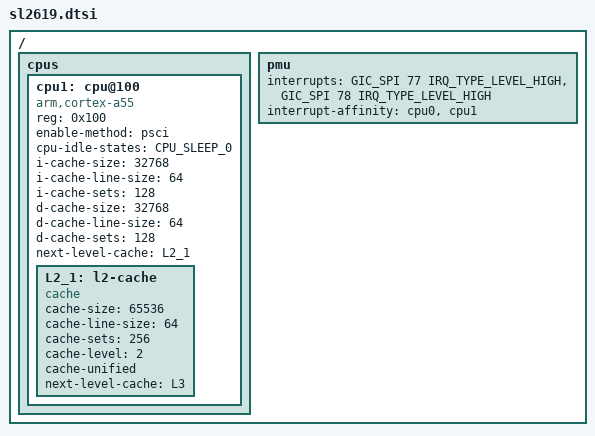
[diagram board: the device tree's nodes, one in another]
// SPDX-License-Identifier: (GPL-2.0 OR MIT)
/*
 * Copyright (C) 2025 Synaptics Incorporated
 *
 * Author: Jisheng Zhang <jszhang@kernel.org>
 */

#include "sl2613.dtsi"

/ {
	cpus {
		cpu1: cpu@100 {
			compatible = "arm,cortex-a55";
			device_type = "cpu";
			reg = <0x100>;
			enable-method = "psci";
			cpu-idle-states = <&CPU_SLEEP_0>;
			i-cache-size = <32768>;
			i-cache-line-size = <64>;
			i-cache-sets = <128>;
			d-cache-size = <32768>;
			d-cache-line-size = <64>;
			d-cache-sets = <128>;
			next-level-cache = <&L2_1>;

			L2_1: l2-cache {
				compatible = "cache";
				cache-size = <65536>;
				cache-line-size = <64>;
				cache-sets = <256>;
				cache-level = <2>;
				cache-unified;
				next-level-cache = <&L3>;
			};
		};
	};

	pmu {
		interrupts = <GIC_SPI 77 IRQ_TYPE_LEVEL_HIGH>,
			     <GIC_SPI 78 IRQ_TYPE_LEVEL_HIGH>;
		interrupt-affinity = <&cpu0>,
				     <&cpu1>;
	};
};
